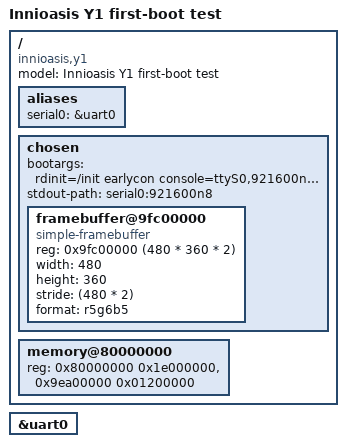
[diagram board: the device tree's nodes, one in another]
// SPDX-License-Identifier: GPL-2.0-only
/*
 * Innioasis Y1 (MT6572) first-boot device tree: CPU0, the MTK timer, the watchdog, UART0 and the frame
 * buffer LK leaves lit, as simple-framebuffer. Nothing else of the board is described or touched.
 * Facts and their evidence: docs/knowledge/y1-hardware.md (owner's player, 2026-11-04).
 * The SoC description is upstream v6.18 arch/arm/boot/dts/mediatek/mt6572.dtsi.
 */
/dts-v1/;
#include "mt6572.dtsi"

/ {
	model = "Innioasis Y1 first-boot test";
	compatible = "innioasis,y1", "mediatek,mt6572";

	aliases {
		serial0 = &uart0;
	};

	chosen {
		#address-cells = <1>;
		#size-cells = <1>;
		ranges;
		/* tty0 last: PID1's console is the screen; UART0 (the stock console, 921600) gets the log too. */
		bootargs = "rdinit=/init earlycon console=ttyS0,921600n8 console=tty0 loglevel=8 ignore_loglevel panic=10";
		stdout-path = "serial0:921600n8";

		/* Stock mtkfb took LK's frame buffer at 0x9fc00000 (/proc/iomem, M4U LCDC_UI); 480x360. */
		framebuffer@9fc00000 {
			compatible = "simple-framebuffer";
			reg = <0x9fc00000 (480 * 360 * 2)>;
			width = <480>;
			height = <360>;
			stride = <(480 * 2)>;
			format = "r5g6b5";
		};
	};

	/*
	 * Stock System RAM, except that the kernel starts at the DRAM base as on the Y2 (AUTO_ZRELADDR):
	 * the first MiB that stock leaves to connsys is idle here. Left out: the 10 MiB at 0x9e000000
	 * whose owner is unknown, and the 4 MiB frame buffer at 0x9fc00000.
	 */
	memory@80000000 {
		device_type = "memory";
		reg = <0x80000000 0x1e000000>, <0x9ea00000 0x01200000>;
	};
};

&uart0 {
	status = "okay";
};
